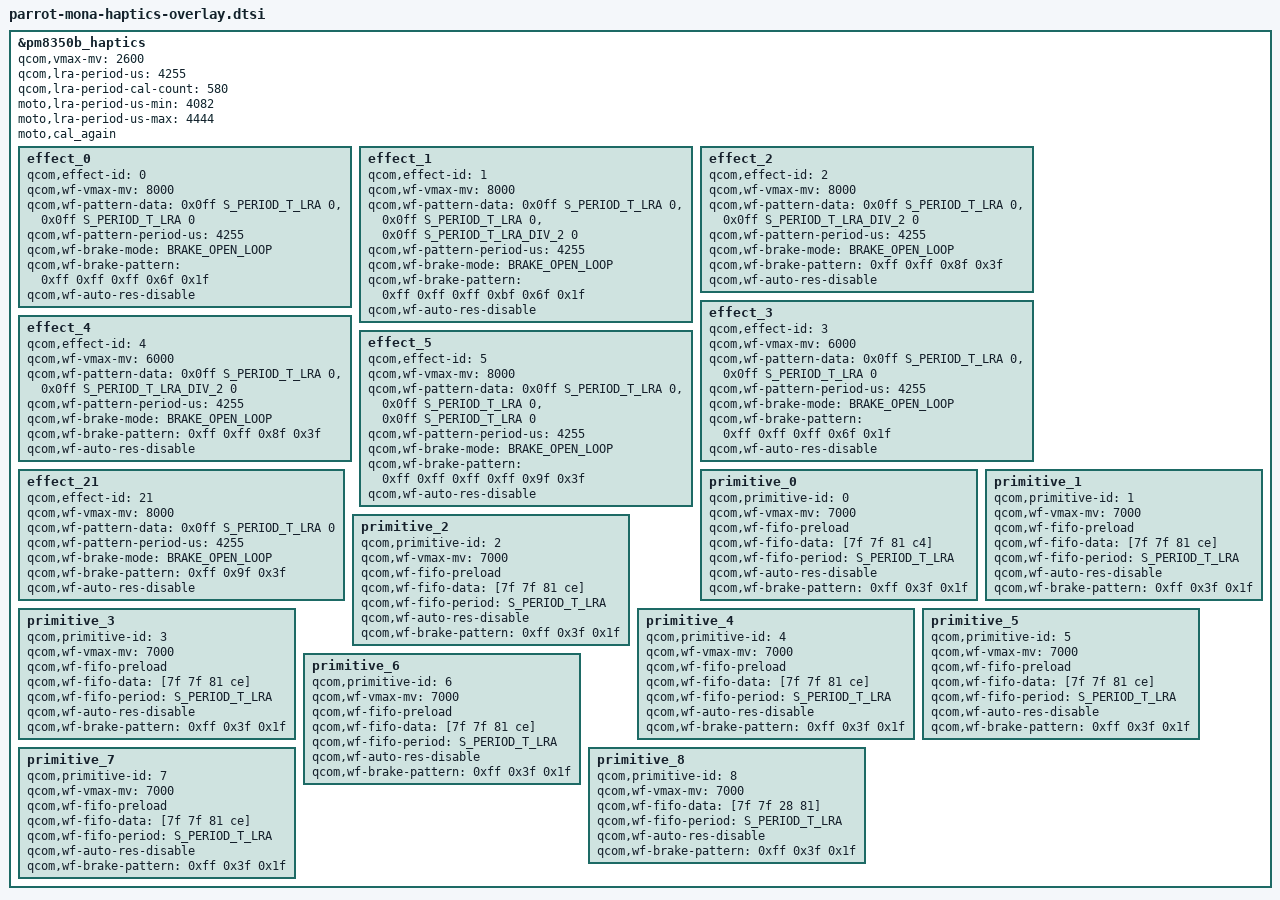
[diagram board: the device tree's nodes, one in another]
/* Copyright (c) 2021, The Linux Foundation. All rights reserved.
 *
 * This program is free software; you can redistribute it and/or modify
 * it under the terms of the GNU General Public License version 2 and
 * only version 2 as published by the Free Software Foundation.
 *
 * This program is distributed in the hope that it will be useful,
 * but WITHOUT ANY WARRANTY; without even the implied warranty of
 * MERCHANTABILITY or FITNESS FOR A PARTICULAR PURPOSE.  See the
 * GNU General Public License for more details.
 */

&pm8350b_haptics {
	qcom,vmax-mv = <2600>;
	qcom,lra-period-us = <4255>;
	qcom,lra-period-cal-count = <580>;
	moto,lra-period-us-min = <4082>;
	moto,lra-period-us-max = <4444>;
	moto,cal_again;
	status = "ok";

	effect_0 {
		/* CLICK */
		qcom,effect-id = <0>;
		qcom,wf-vmax-mv = <8000>;
		qcom,wf-pattern-data =  <0x0ff  S_PERIOD_T_LRA  0>,
					<0x0ff  S_PERIOD_T_LRA  0>;
		qcom,wf-pattern-period-us = <4255>;
		qcom,wf-brake-mode = <BRAKE_OPEN_LOOP>;
		qcom,wf-brake-pattern = /bits/ 8 <0xff 0xff 0xff 0x6f 0x1f>;
		qcom,wf-auto-res-disable;
	};

	effect_1 {
		/* DOUBLE_CLICK */
		qcom,effect-id = <1>;
		qcom,wf-vmax-mv = <8000>;
		qcom,wf-pattern-data =  <0x0ff  S_PERIOD_T_LRA  0>,
					<0x0ff  S_PERIOD_T_LRA  0>,
					<0x0ff  S_PERIOD_T_LRA_DIV_2 0>;
		qcom,wf-pattern-period-us = <4255>;
		qcom,wf-brake-mode = <BRAKE_OPEN_LOOP>;
		qcom,wf-brake-pattern = /bits/ 8 <0xff 0xff 0xff 0xbf 0x6f 0x1f>;
		qcom,wf-auto-res-disable;
	};

	effect_2 {
		/* TICK */
		qcom,effect-id = <2>;
		qcom,wf-vmax-mv = <8000>;
		qcom,wf-pattern-data =  <0x0ff  S_PERIOD_T_LRA  0>,
					<0x0ff  S_PERIOD_T_LRA_DIV_2 0>;
		qcom,wf-pattern-period-us = <4255>;
		qcom,wf-brake-mode = <BRAKE_OPEN_LOOP>;
		qcom,wf-brake-pattern = /bits/ 8 <0xff 0xff 0x8f 0x3f>;
		qcom,wf-auto-res-disable;
	};

	effect_3 {
		/* THUD */
		qcom,effect-id = <3>;
		qcom,wf-vmax-mv = <6000>;
		qcom,wf-pattern-data =  <0x0ff  S_PERIOD_T_LRA  0>,
					<0x0ff  S_PERIOD_T_LRA  0>;
		qcom,wf-pattern-period-us = <4255>;
		qcom,wf-brake-mode = <BRAKE_OPEN_LOOP>;
		qcom,wf-brake-pattern = /bits/ 8 <0xff 0xff 0xff 0x6f 0x1f>;
		qcom,wf-auto-res-disable;
	};

	effect_4 {
		/* POP */
		qcom,effect-id = <4>;
		qcom,wf-vmax-mv = <6000>;
		qcom,wf-pattern-data =  <0x0ff  S_PERIOD_T_LRA  0>,
					<0x0ff  S_PERIOD_T_LRA_DIV_2 0>;
		qcom,wf-pattern-period-us = <4255>;
		qcom,wf-brake-mode = <BRAKE_OPEN_LOOP>;
		qcom,wf-brake-pattern = /bits/ 8 <0xff 0xff 0x8f 0x3f>;
		qcom,wf-auto-res-disable;
	};

	effect_5 {
		/* HEAVY CLICK */
		qcom,effect-id = <5>;
		qcom,wf-vmax-mv = <8000>;
		qcom,wf-pattern-data =  <0x0ff  S_PERIOD_T_LRA  0>,
					<0x0ff  S_PERIOD_T_LRA  0>,
					<0x0ff  S_PERIOD_T_LRA 0>;
		qcom,wf-pattern-period-us = <4255>;
		qcom,wf-brake-mode = <BRAKE_OPEN_LOOP>;
		qcom,wf-brake-pattern = /bits/ 8 <0xff 0xff 0xff 0xff 0x9f 0x3f>;
		qcom,wf-auto-res-disable;
	};

	effect_21 {
		/* TEXTURE_TICK */
		qcom,effect-id = <21>;
		qcom,wf-vmax-mv = <8000>;
		qcom,wf-pattern-data =  <0x0ff  S_PERIOD_T_LRA  0>;
		qcom,wf-pattern-period-us = <4255>;
		qcom,wf-brake-mode = <BRAKE_OPEN_LOOP>;
		qcom,wf-brake-pattern = /bits/ 8 <0xff 0x9f 0x3f>;
		qcom,wf-auto-res-disable;
	};

	primitive_0 {
		/* NOOP */
		qcom,primitive-id = <0>;
		qcom,wf-vmax-mv = <7000>;
		qcom,wf-fifo-preload;
		qcom,wf-fifo-data = [7f 7f 81 c4];
		qcom,wf-fifo-period = <S_PERIOD_T_LRA>;
		qcom,wf-auto-res-disable;
		qcom,wf-brake-pattern = /bits/ 8 <0xff 0x3f 0x1f>;
		/delete-property/ qcom,wf-brake-disable;
	};

	primitive_1 {
		/* CLICK */
		qcom,primitive-id = <1>;
		qcom,wf-vmax-mv = <7000>;
		qcom,wf-fifo-preload;
		qcom,wf-fifo-data = [7f 7f 81 ce];
		qcom,wf-fifo-period = <S_PERIOD_T_LRA>;
		qcom,wf-auto-res-disable;
		qcom,wf-brake-pattern = /bits/ 8 <0xff 0x3f 0x1f>;
		/delete-property/ qcom,wf-brake-disable;
	};

	primitive_2 {
		/* THUD */
		qcom,primitive-id = <2>;
		qcom,wf-vmax-mv = <7000>;
		qcom,wf-fifo-preload;
		qcom,wf-fifo-data = [7f 7f 81 ce];
		qcom,wf-fifo-period = <S_PERIOD_T_LRA>;
		qcom,wf-auto-res-disable;
		qcom,wf-brake-pattern = /bits/ 8 <0xff 0x3f 0x1f>;
		/delete-property/ qcom,wf-brake-disable;
	};

	primitive_3 {
		/* SPIN */
		qcom,primitive-id = <3>;
		qcom,wf-vmax-mv = <7000>;
		qcom,wf-fifo-preload;
		qcom,wf-fifo-data = [7f 7f 81 ce];
		qcom,wf-fifo-period = <S_PERIOD_T_LRA>;
		qcom,wf-auto-res-disable;
		qcom,wf-brake-pattern = /bits/ 8 <0xff 0x3f 0x1f>;
		/delete-property/ qcom,wf-brake-disable;
	};

	primitive_4 {
		/* QUICK_RISE */
		qcom,primitive-id = <4>;
		qcom,wf-vmax-mv = <7000>;
		qcom,wf-fifo-preload;
		qcom,wf-fifo-data = [7f 7f 81 ce];
		qcom,wf-fifo-period = <S_PERIOD_T_LRA>;
		qcom,wf-auto-res-disable;
		qcom,wf-brake-pattern = /bits/ 8 <0xff 0x3f 0x1f>;
		/delete-property/ qcom,wf-brake-disable;
	};

	primitive_5 {
		/* SLOW_RISE */
		qcom,primitive-id = <5>;
		qcom,wf-vmax-mv = <7000>;
		qcom,wf-fifo-preload;
		qcom,wf-fifo-data = [7f 7f 81 ce];
		qcom,wf-fifo-period = <S_PERIOD_T_LRA>;
		qcom,wf-auto-res-disable;
		qcom,wf-brake-pattern = /bits/ 8 <0xff 0x3f 0x1f>;
		/delete-property/ qcom,wf-brake-disable;
	};

	primitive_6 {
		/* QUICK_FALL */
		qcom,primitive-id = <6>;
		qcom,wf-vmax-mv = <7000>;
		qcom,wf-fifo-preload;
		qcom,wf-fifo-data = [7f 7f 81 ce];
		qcom,wf-fifo-period = <S_PERIOD_T_LRA>;
		qcom,wf-auto-res-disable;
		qcom,wf-brake-pattern = /bits/ 8 <0xff 0x3f 0x1f>;
		/delete-property/ qcom,wf-brake-disable;
	};

	primitive_7 {
		/* LIGHT_TICK */
		qcom,primitive-id = <7>;
		qcom,wf-vmax-mv = <7000>;
		qcom,wf-fifo-preload;
		qcom,wf-fifo-data = [7f 7f 81 ce];
		qcom,wf-fifo-period = <S_PERIOD_T_LRA>;
		qcom,wf-auto-res-disable;
		qcom,wf-brake-pattern = /bits/ 8 <0xff 0x3f 0x1f>;
		/delete-property/ qcom,wf-brake-disable;
	};

	primitive_8 {
		/* LOW_TICK */
		qcom,primitive-id = <8>;
		qcom,wf-vmax-mv = <7000>;
		/delete-property/ qcom,wf-fifo-preload;
		qcom,wf-fifo-data = [7f 7f 28 81];
		qcom,wf-fifo-period = <S_PERIOD_T_LRA>;
		qcom,wf-auto-res-disable;
		qcom,wf-brake-pattern = /bits/ 8 <0xff 0x3f 0x1f>;
		/delete-property/ qcom,wf-brake-disable;
	};
};

